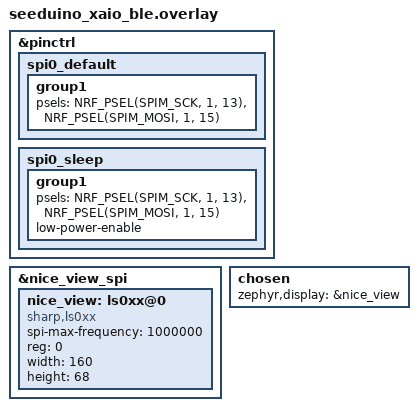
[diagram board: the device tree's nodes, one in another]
/*
 * Copyright (c) 2024 The ZMK Contributors
 * SPDX-License-Identifier: MIT
 */

&pinctrl {
    spi0_default: spi0_default {
        group1 {
            psels = <NRF_PSEL(SPIM_SCK, 1, 13)>,
                <NRF_PSEL(SPIM_MOSI, 1, 15)>;
        };
    };
    spi0_sleep: spi0_sleep {
        group1 {
            psels = <NRF_PSEL(SPIM_SCK, 1, 13)>,
                <NRF_PSEL(SPIM_MOSI, 1, 15)>;
            low-power-enable;
        };
    };
};

&nice_view_spi {
    status = "okay";
    nice_view: ls0xx@0 {
        compatible = "sharp,ls0xx";
        spi-max-frequency = <1000000>;
        reg = <0>;
        width = <160>;
        height = <68>;
    };
};

chosen {
    zephyr,display = &nice_view;
};

/* nice_view_spi: &spi0 { */
/*     compatible = "nordic,nrf-spim"; */
/*     pinctrl-0 = <&spi0_default>; */
/*     pinctrl-1 = <&spi0_sleep>; */
/*     pinctrl-names = "default", "sleep"; */
/*     cs-gpios = <&xiao_d 7 GPIO_ACTIVE_LOW>, <&xiao_d 6 GPIO_ACTIVE_HIGH>; */
/* }; */
/**/
/* &xiao_i2c { status = "disabled"; }; */
/* &xiao_serial { status = "disabled"; }; */
